# MIMXRT685S_cm33 register map
Vendor: nxp.com; File version: 1.0
CPU: CM33 r2p0, little endian, MPU, FPU, VTOR, 3 interrupt priority bits
Registers are 32-bit, read-write, reset 0x0 unless marked. A register's access mark holds for its fields unless they carry their own. Offsets are from the block's base; [hi:lo] are bit positions.

## RSTCTL0 — reset ccontroller 0
Base 0x40000000
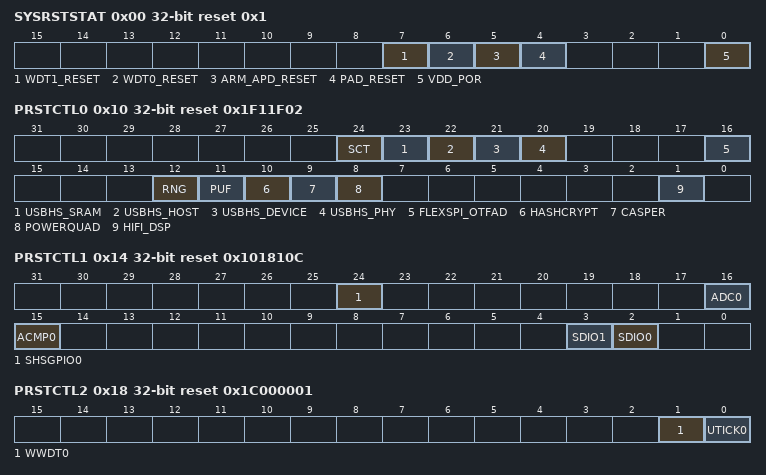
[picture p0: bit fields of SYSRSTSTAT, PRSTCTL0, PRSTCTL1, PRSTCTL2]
0x00 SYSRSTSTAT reset 0x1 — system reset status register
  [7] WDT1_RESET — WDT1 RESET Event Detected:
    0=NO_EVENT_DETECTED; 1=WDT1_RESET_DETECTED (WDT1 reset event detected. (Writing a 1 to this bit clears this status).)
  [6] WDT0_RESET — WDT0 RESET Event Detected:
    0=NO_EVENT_DETECTED; 1=WDT0_RESET_DETECTED (WDT0 reset event detected. (Writing a '1' to this bit clears this status).)
  [5] ARM_APD_RESET — ARM RESET Event Detected:
    0=NO_EVENT_DETECTED; 1=RESET_DETECTED (ARM reset event detected. (Writing a '1' to this bit clears this status).)
  [4] PAD_RESET — PAD RESET Event Detected:
    0=NO_EVENT_DETECTED; 1=RESET_DETECTED (RESET Detected. (Write 1 to CLR),)
  [0] VDD_POR — VDD POR Event Detected:
    0=NO_EVENT_DETECTED; 1=POR_EVENT_DETECTED (VDD POR event detected. (Writing a '1' to this bit clears this status).)
0x10 PRSTCTL0 reset 0x1F11F02 — peripheral reset control register 0
  [all] fields
    0=CLEAR_RESET; 1=SET_RESET
  [24] SCT — SCT reset control
  [23] USBHS_SRAM — USBHS RAM reset control
  [22] USBHS_HOST — USB HOST reset control
  [21] USBHS_DEVICE — USB DEVICE reset control
  [20] USBHS_PHY — USB PHY reset control
  [16] FLEXSPI_OTFAD — FLEXSPI reset control
  [12] RNG — RNG reset control
  [11] PUF — PUF reset control
  [10] HASHCRYPT — HASHCRYPT reset control
  [9] CASPER — CAPSER reset control
  [8] POWERQUAD — powerquad reset control
  [1] HIFI_DSP — HIFI DSP reset control
0x14 PRSTCTL1 reset 0x101810C — peripheral reset control register 1
  [all] fields
    0=CLEAR_RESET; 1=SET_RESET
  [24] SHSGPIO0 — SHSGPIO0 reset control
  [16] ADC0 — ADC reset control
  [15] ACMP0 — Analog comparator reset control
  [3] SDIO1 — SDIO1 reset control
  [2] SDIO0 — SDIO0 reset control
0x18 PRSTCTL2 reset 0x1C000001 — peripheral reset control register 2
  [1] WWDT0 — wdt reset control
    0=CLEAR_RESET; 1=SET_RESET
  [0] UTICK0 — utick reset control
    0=CLEAR_RESET; 1=SET_RESET
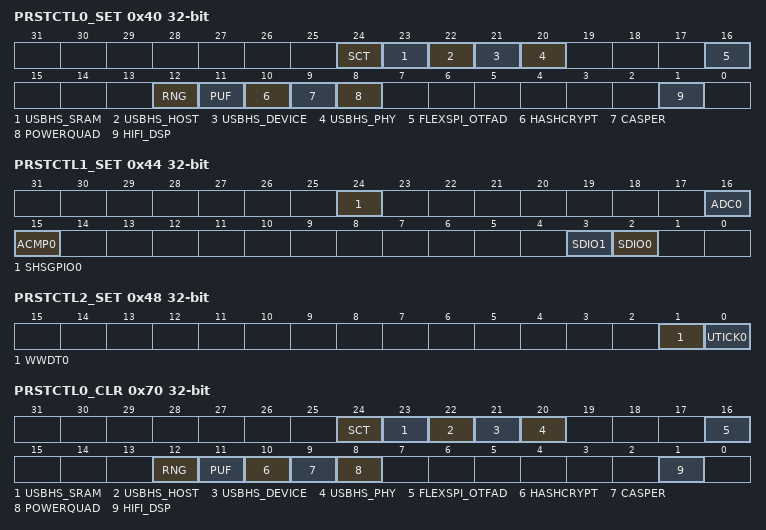
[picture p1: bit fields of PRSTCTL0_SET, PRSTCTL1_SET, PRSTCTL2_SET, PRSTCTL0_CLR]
0x40 PRSTCTL0_SET reset not defined — peripheral reset set register 0
  [all] fields
    0=NO_EFFECT; 1=SET_RESET (Sets the PRSTCTL0 Bit)
  [24] SCT wo — SCT reset set
  [23] USBHS_SRAM wo — USBHS RAM reset set
  [22] USBHS_HOST wo — USB HOST reset set
  [21] USBHS_DEVICE wo — USB DEVICE reset set
  [20] USBHS_PHY wo — USB PHY reset set
  [16] FLEXSPI_OTFAD wo — FLEXSPI reset set
  [12] RNG wo — RNG reset set
  [11] PUF wo — PUF reset set
  [10] HASHCRYPT wo — HASHCRYPT reset set
  [9] CASPER wo — CAPSER reset set
  [8] POWERQUAD wo — powerquad reset set
  [1] HIFI_DSP wo — HIFI DSP reset set
0x44 PRSTCTL1_SET reset not defined — peripheral reset set register 1
  [all] fields
    0=NO_EFFECT; 1=SET_RESET (Sets the PRSTCTL1 Bit)
  [24] SHSGPIO0 wo — SHSGPIO0 reset set
  [16] ADC0 wo — ADC reset set
  [15] ACMP0 wo — Analog comparator reset set
  [3] SDIO1 wo — SDIO1 reset set
  [2] SDIO0 wo — SDIO0 reset set
0x48 PRSTCTL2_SET reset not defined — peripheral reset set register 2
  [1] WWDT0 wo — wdt reset set
    0=NO_EFFECT; 1=SET_RESET (Sets the PRSTCTL2 Bit)
  [0] UTICK0 wo — utick reset set
    0=NO_EFFECT; 1=SET_RESET (Sets the PRSTCTL2 Bit)
0x70 PRSTCTL0_CLR reset not defined — peripheral reset clear register 0
  [all] fields
    0=NO_EFFECT; 1=CLR_RESET (Clears the PRSTCTL0 Bit)
  [24] SCT wo — SCT reset clear
  [23] USBHS_SRAM wo — USBHS RAM reset clear
  [22] USBHS_HOST wo — USB HOST reset clear
  [21] USBHS_DEVICE wo — USB DEVICE reset clear
  [20] USBHS_PHY wo — USB PHY reset clear
  [16] FLEXSPI_OTFAD wo — FLEXSPI reset clear
  [12] RNG wo — RNG reset clear
  [11] PUF wo — PUF reset clear
  [10] HASHCRYPT wo — HASHCRYPT reset clear
  [9] CASPER wo — CAPSER reset clear
  [8] POWERQUAD wo — powerquad reset clear
  [1] HIFI_DSP wo — HIFI DSP reset clear
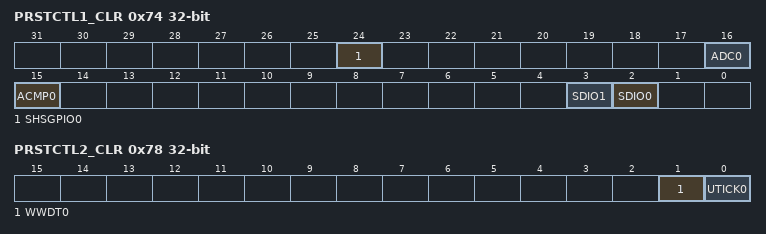
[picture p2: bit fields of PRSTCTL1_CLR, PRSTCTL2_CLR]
0x74 PRSTCTL1_CLR reset not defined — peripheral reset clear register 1
  [all] fields
    0=NO_EFFECT; 1=CLR_RESET (Clears the PRSTCTL1 Bit)
  [24] SHSGPIO0 wo — SHSGPIO0 reset clear
  [16] ADC0 wo — ADC reset clear
  [15] ACMP0 wo — Analog comparator reset clear
  [3] SDIO1 wo — SDIO1 reset clear
  [2] SDIO0 wo — SDIO0 reset clear
0x78 PRSTCTL2_CLR reset not defined — peripheral reset clear register 2
  [1] WWDT0 wo — wdt reset clear
    0=NO_EFFECT; 1=CLR_RESET (Clears the PRSTCTL2 Bit)
  [0] UTICK0 wo — utick reset clear
    0=NO_EFFECT; 1=CLR_RESET (Clears the PRSTCTL2 Bit)

## Notices in the file
Copyright 2016-2020 NXP
All rights reserved.
SPDX-License-Identifier: BSD-3-Clause
